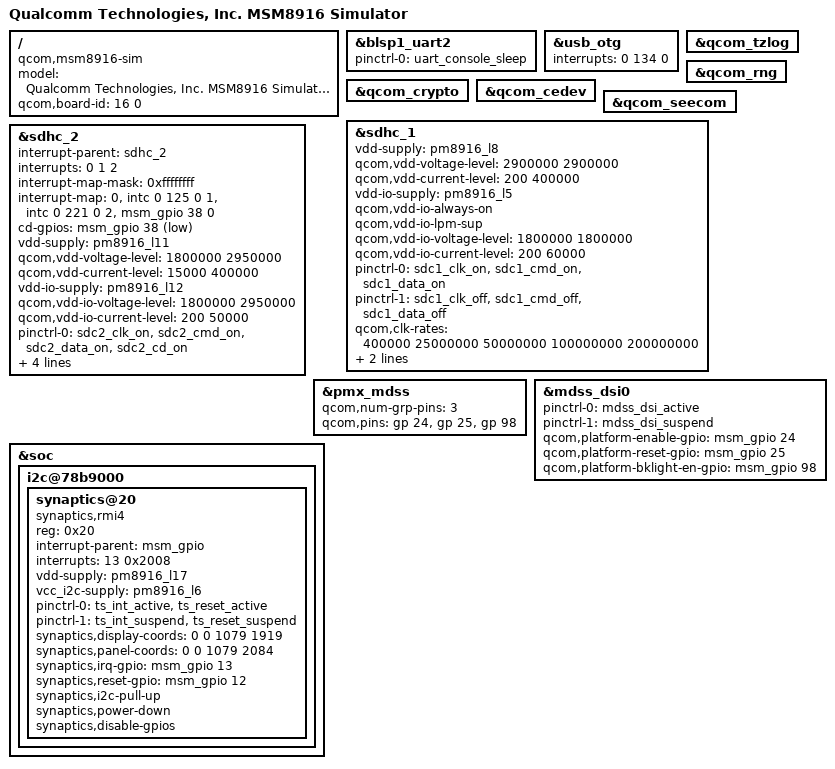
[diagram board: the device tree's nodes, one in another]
/* Copyright (c) 2013-2014, The Linux Foundation. All rights reserved.
 *
 * This program is free software; you can redistribute it and/or modify
 * it under the terms of the GNU General Public License version 2 and
 * only version 2 as published by the Free Software Foundation.
 *
 * This program is distributed in the hope that it will be useful,
 * but WITHOUT ANY WARRANTY; without even the implied warranty of
 * MERCHANTABILITY or FITNESS FOR A PARTICULAR PURPOSE.  See the
 * GNU General Public License for more details.
 */

/dts-v1/;

/memreserve/ 0x80000000 0x00000100;

#include "msm8916.dtsi"
#include "msm8916-pinctrl.dtsi"
#include "msm8916-memory.dtsi"

/ {
	model = "Qualcomm Technologies, Inc. MSM8916 Simulator";
	compatible = "qcom,msm8916-sim", "qcom,msm8916", "qcom,sim";
	qcom,board-id= <16 0>;
};

&blsp1_uart2 {
	status = "ok";
	pinctrl-names = "default";
	pinctrl-0 = <&uart_console_sleep>;
};

&usb_otg {
	interrupts = <0 134 0>;
	interrupt-names = "core_irq";
};

&qcom_tzlog {
	status = "okay";
};

&qcom_rng {
	status = "okay";
};

&qcom_crypto {
	status = "okay";
};

&qcom_cedev {
	status = "okay";
};

&qcom_seecom {
	status = "okay";
};

&sdhc_1 {
	vdd-supply = <&pm8916_l8>;
	qcom,vdd-voltage-level = <2900000 2900000>;
	qcom,vdd-current-level = <200 400000>;

	vdd-io-supply = <&pm8916_l5>;
	qcom,vdd-io-always-on;
	qcom,vdd-io-lpm-sup;
	qcom,vdd-io-voltage-level = <1800000 1800000>;
	qcom,vdd-io-current-level = <200 60000>;

	pinctrl-names = "active", "sleep";
	pinctrl-0 = <&sdc1_clk_on &sdc1_cmd_on &sdc1_data_on>;
	pinctrl-1 = <&sdc1_clk_off &sdc1_cmd_off &sdc1_data_off>;

	qcom,clk-rates = <400000 25000000 50000000 100000000 200000000>;
	qcom,bus-speed-mode = "HS200_1p8v", "DDR_1p8v";
	qcom,nonremovable;

	status = "ok";
};

&sdhc_2 {
	 #address-cells = <0>;
	interrupt-parent = <&sdhc_2>;
	interrupts = <0 1 2>;
	#interrupt-cells = <1>;
	interrupt-map-mask = <0xffffffff>;
	interrupt-map = <0 &intc 0 125 0
			1 &intc 0 221 0
			2 &msm_gpio 38 0>;
	interrupt-names = "hc_irq", "pwr_irq", "status_irq";
	cd-gpios = <&msm_gpio 38 0x1>;

	vdd-supply = <&pm8916_l11>;
	qcom,vdd-voltage-level = <1800000 2950000>;
	qcom,vdd-current-level = <15000 400000>;

	vdd-io-supply = <&pm8916_l12>;
	qcom,vdd-io-voltage-level = <1800000 2950000>;
	qcom,vdd-io-current-level = <200 50000>;

	pinctrl-names = "active", "sleep";
	pinctrl-0 = <&sdc2_clk_on &sdc2_cmd_on &sdc2_data_on &sdc2_cd_on>;
	pinctrl-1 = <&sdc2_clk_off &sdc2_cmd_off &sdc2_data_off &sdc2_cd_off>;

	qcom,clk-rates = <400000 25000000 50000000 100000000 200000000>;

	status = "ok";
};

&pmx_mdss {
		qcom,num-grp-pins = <3>;
		qcom,pins = <&gp 24>, <&gp 25>, <&gp 98>;
};

&mdss_dsi0 {
		pinctrl-names = "mdss_default", "mdss_sleep";
		pinctrl-0 = <&mdss_dsi_active>;
		pinctrl-1 = <&mdss_dsi_suspend>;

		qcom,platform-enable-gpio = <&msm_gpio 24 0>;
		qcom,platform-reset-gpio = <&msm_gpio 25 0>;
		qcom,platform-bklight-en-gpio = <&msm_gpio 98 0>;
};

&soc {
	i2c@78b9000 { /* BLSP1 QUP5 */
		synaptics@20 {
			compatible = "synaptics,rmi4";
			reg = <0x20>;
			interrupt-parent = <&msm_gpio>;
			interrupts = <13 0x2008>;
			vdd-supply = <&pm8916_l17>;
			vcc_i2c-supply = <&pm8916_l6>;
			/* pins used by touchscreen */
			pinctrl-names = "pmx_ts_active","pmx_ts_suspend";
			pinctrl-0 = <&ts_int_active &ts_reset_active>;
			pinctrl-1 = <&ts_int_suspend &ts_reset_suspend>;
			synaptics,display-coords = <0 0 1079 1919>;
			synaptics,panel-coords = <0 0 1079 2084>;
			synaptics,irq-gpio = <&msm_gpio 13 0x2008>;
			synaptics,reset-gpio = <&msm_gpio 12 0x0>;
			synaptics,i2c-pull-up;
			synaptics,power-down;
			synaptics,disable-gpios;
		};
	};
};
